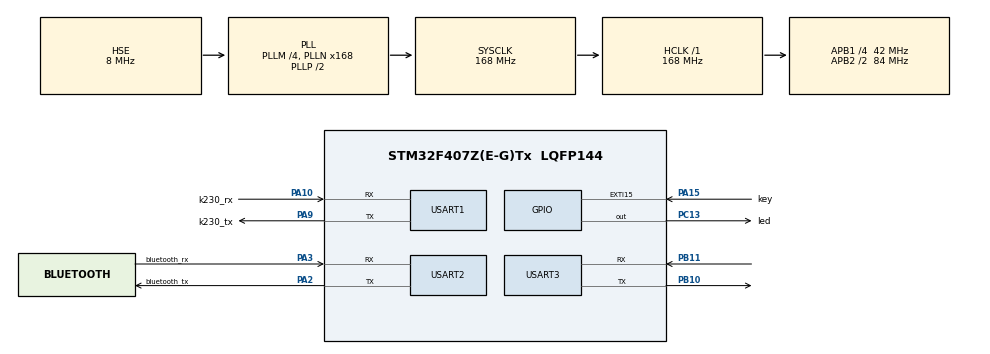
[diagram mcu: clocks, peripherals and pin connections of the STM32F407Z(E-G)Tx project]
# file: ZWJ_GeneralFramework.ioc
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Dma.Request0=USART1_RX
Dma.Request1=USART1_TX
Dma.Request2=USART2_RX
Dma.Request3=USART2_TX
Dma.USART1_RX.0.Direction=DMA_PERIPH_TO_MEMORY
Dma.USART1_RX.0.FIFOMode=DMA_FIFOMODE_DISABLE
Dma.USART1_RX.0.Instance=DMA2_Stream2
Dma.USART1_RX.0.MemDataAlignment=DMA_MDATAALIGN_BYTE
Dma.USART1_RX.0.MemInc=DMA_MINC_ENABLE
Dma.USART1_RX.0.Mode=DMA_NORMAL
Dma.USART1_RX.0.PeriphDataAlignment=DMA_PDATAALIGN_BYTE
Dma.USART1_RX.0.PeriphInc=DMA_PINC_DISABLE
Dma.USART1_RX.0.Priority=DMA_PRIORITY_LOW
Dma.USART1_TX.1.Direction=DMA_MEMORY_TO_PERIPH
Dma.USART1_TX.1.FIFOMode=DMA_FIFOMODE_DISABLE
Dma.USART1_TX.1.Instance=DMA2_Stream7
Dma.USART1_TX.1.MemDataAlignment=DMA_MDATAALIGN_BYTE
Dma.USART1_TX.1.MemInc=DMA_MINC_ENABLE
Dma.USART1_TX.1.Mode=DMA_NORMAL
Dma.USART1_TX.1.PeriphDataAlignment=DMA_PDATAALIGN_BYTE
Dma.USART1_TX.1.PeriphInc=DMA_PINC_DISABLE
Dma.USART1_TX.1.Priority=DMA_PRIORITY_LOW
Dma.USART2_RX.2.Direction=DMA_PERIPH_TO_MEMORY
Dma.USART2_RX.2.FIFOMode=DMA_FIFOMODE_DISABLE
Dma.USART2_RX.2.Instance=DMA1_Stream5
Dma.USART2_RX.2.MemDataAlignment=DMA_MDATAALIGN_BYTE
Dma.USART2_RX.2.MemInc=DMA_MINC_ENABLE
Dma.USART2_RX.2.Mode=DMA_NORMAL
Dma.USART2_RX.2.PeriphDataAlignment=DMA_PDATAALIGN_BYTE
Dma.USART2_RX.2.PeriphInc=DMA_PINC_DISABLE
Dma.USART2_RX.2.Priority=DMA_PRIORITY_LOW
Dma.USART2_TX.3.Direction=DMA_MEMORY_TO_PERIPH
Dma.USART2_TX.3.FIFOMode=DMA_FIFOMODE_DISABLE
Dma.USART2_TX.3.Instance=DMA1_Stream6
Dma.USART2_TX.3.MemDataAlignment=DMA_MDATAALIGN_BYTE
Dma.USART2_TX.3.MemInc=DMA_MINC_ENABLE
Dma.USART2_TX.3.Mode=DMA_NORMAL
Dma.USART2_TX.3.PeriphDataAlignment=DMA_PDATAALIGN_BYTE
Dma.USART2_TX.3.PeriphInc=DMA_PINC_DISABLE
Dma.USART2_TX.3.Priority=DMA_PRIORITY_LOW
FREERTOS.INCLUDE_vTaskDelayUntil=1
FREERTOS.Tasks01=ApplicationTask,0,2048,Application,Default,NULL,Dynamic,NULL,NULL;ControlTask,2,512,Control,Default,NULL,Dynamic,NULL,NULL;RobotSystemTask,-2,512,RobotSystem,Default,NULL,Dynamic,NULL,NULL;StateCoreTask,1,1024,StateCore,Default,NULL,Dynamic,NULL,NULL
FREERTOS.configTOTAL_HEAP_SIZE=20000
Mcu.Family=STM32F4
Mcu.Name=STM32F407Z(E-G)Tx
Mcu.Package=LQFP144
NVIC.DMA1_Stream5_IRQn=true\:5\:0\:false\:false\:true\:true\:false\:true\:true
NVIC.DMA1_Stream6_IRQn=true\:5\:0\:false\:false\:true\:true\:false\:true\:true
NVIC.DMA2_Stream2_IRQn=true\:5\:0\:false\:false\:true\:true\:false\:true\:true
NVIC.DMA2_Stream7_IRQn=true\:5\:0\:false\:false\:true\:true\:false\:true\:true
NVIC.EXTI15_10_IRQn=true\:5\:0\:false\:false\:true\:false\:true\:true\:true
NVIC.PriorityGroup=NVIC_PRIORITYGROUP_4
NVIC.TIM6_DAC_IRQn=true\:15\:0\:false\:false\:true\:false\:false\:true\:true
NVIC.TimeBase=TIM6_DAC_IRQn
NVIC.TimeBaseIP=TIM6
NVIC.USART1_IRQn=true\:5\:0\:false\:false\:true\:true\:true\:true\:true
NVIC.USART2_IRQn=true\:5\:0\:false\:false\:true\:true\:true\:true\:true
PA10.GPIO_Label=k230_rx
PA10.Mode=Asynchronous
PA10.Signal=USART1_RX
PA13.Mode=Serial_Wire
PA13.Signal=SYS_JTMS-SWDIO
PA14.Mode=Serial_Wire
PA14.Signal=SYS_JTCK-SWCLK
PA15.GPIO_Label=key
PA15.GPIO_ModeDefaultEXTI=GPIO_MODE_IT_FALLING
PA15.GPIO_PuPd=GPIO_PULLUP
PA15.Signal=GPXTI15
PA2.GPIO_Label=bluetooth_tx
PA2.Mode=Asynchronous
PA2.Signal=USART2_TX
PA3.GPIO_Label=bluetooth_rx
PA3.Mode=Asynchronous
PA3.Signal=USART2_RX
PA9.GPIO_Label=k230_tx
PA9.Mode=Asynchronous
PA9.Signal=USART1_TX
PB10.Mode=Asynchronous
PB10.Signal=USART3_TX
PB11.Mode=Asynchronous
PB11.Signal=USART3_RX
PC13-ANTI_TAMP.GPIO_Label=led
PC13-ANTI_TAMP.GPIO_PuPd=GPIO_PULLUP
PC13-ANTI_TAMP.PinState=GPIO_PIN_SET
PC13-ANTI_TAMP.Signal=GPIO_Output
PC14-OSC32_IN.Mode=LSE-External-Oscillator
PC14-OSC32_IN.Signal=RCC_OSC32_IN
PC15-OSC32_OUT.Mode=LSE-External-Oscillator
PC15-OSC32_OUT.Signal=RCC_OSC32_OUT
PH0-OSC_IN.Mode=HSE-External-Oscillator
PH0-OSC_IN.Signal=RCC_OSC_IN
PH1-OSC_OUT.Mode=HSE-External-Oscillator
PH1-OSC_OUT.Signal=RCC_OSC_OUT
ProjectManager.HeapSize=0x200
ProjectManager.StackSize=0x400
ProjectManager.TargetToolchain=MDK-ARM V5.32
RCC.48MHZClocksFreq_Value=84000000
RCC.AHBFreq_Value=168000000
RCC.APB1CLKDivider=RCC_HCLK_DIV4
RCC.APB1Freq_Value=42000000
RCC.APB1TimFreq_Value=84000000
RCC.APB2CLKDivider=RCC_HCLK_DIV2
RCC.APB2Freq_Value=84000000
RCC.APB2TimFreq_Value=168000000
RCC.CortexFreq_Value=168000000
RCC.HCLKFreq_Value=168000000
RCC.HSE_VALUE=8000000
RCC.HSI_VALUE=16000000
RCC.PLLM=4
RCC.PLLN=168
RCC.PLLSourceVirtual=RCC_PLLSOURCE_HSE
RCC.SYSCLKFreq_VALUE=168000000
RCC.SYSCLKSource=RCC_SYSCLKSOURCE_PLLCLK
RCC.VCOOutputFreq_Value=336000000
STMicroelectronics.X-CUBE-ALGOBUILD.1.4.0.LibraryCcDSPOoLibraryJjDSPOoLibrary=true
USART1.VirtualMode=VM_ASYNC
USART2.VirtualMode=VM_ASYNC
USART3.VirtualMode=VM_ASYNC
VP_FREERTOS_VS_CMSIS_V1.Mode=CMSIS_V1
VP_STMicroelectronics.X-CUBE-ALGOBUILD_VS_DSPOoLibraryJjLibrary_1.4.0_1.4.0.Mode=DSPOoLibraryJjLibrary
VP_SYS_VS_tim6.Mode=TIM6
board=custom

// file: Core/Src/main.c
/* USER CODE BEGIN Header */
////////////////////////////////////////////////////////////////////
//                          _ooOoo_                               //
//                         o8888888o                              //
//                         88" . "88                              //
//                         (| ^_^ |)                              //
//                         O\  =  /O                              //
//                      ____/`---'\____                           //
//                    .'  \\|     |//  `.                         //
//                   /  \\|||  :  |||//  \                        //
//                  /  _||||| -:- |||||-  \                       //
//                  |   | \\\  -  /// |   |                       //
//                  | \_|  ''\---/''  |   |                       //
//                  \  .-\__  `-`  ___/-. /                       //
//                ___`. .'  /--.--\  `. . ___                     //
//              ."" '<  `.___\_<|>_/___.'  >'"".                  //
//            | | :  `- \`.;`\ _ /`;.`/ - ` : | |                 //
//            \  \ `-.   \_ __\ /__ _/   .-` /  /                 //
//      ========`-.____`-.___\_____/___.-`____.-'========         //
//                           `=---='                              //
//      ^^^^^^^^^^^^^^^^^^^^^^^^^^^^^^^^^^^^^^^^^^^^^^^^^^        //
//          佛祖保佑          永不宕机          永无BUG            //
////////////////////////////////////////////////////////////////////
/**
 ******************************************************************************
 * @file           : main.c
 * @brief          : Main program body
 ******************************************************************************
 * @attention
 *
 * Copyright (c) 2026 STMicroelectronics.
 * All rights reserved.
 *
 * This software is licensed under terms that can be found in the LICENSE file
 * in the root directory of this software component.
 * If no LICENSE file comes with this software, it is provided AS-IS.
 *
 ******************************************************************************
 */
/* USER CODE END Header */
#include "main.h"
#include "cmsis_os.h"
#include "dma.h"
#include "usart.h"
#include "gpio.h"

/* USER CODE BEGIN Includes */
#include "std_cpp.h"
/* USER CODE END Includes */

void SystemClock_Config(void);
void MX_FREERTOS_Init(void);

int main(void)
{

  /* MCU Configuration--------------------------------------------------------*/

  /* Reset of all peripherals, Initializes the Flash interface and the Systick. */
  HAL_Init();

  /* Configure the system clock */
  SystemClock_Config();

  /* Initialize all configured peripherals */
  MX_GPIO_Init();
  MX_DMA_Init();
  MX_USART1_UART_Init();
  MX_USART2_UART_Init();
  MX_USART3_UART_Init();
  /* USER CODE BEGIN 2 */
    MainInitCpp();
  /* USER CODE END 2 */

  /* Call init function for freertos objects (in cmsis_os2.c) */
  MX_FREERTOS_Init();

  /* Start scheduler */
  osKernelStart();

  /* We should never get here as control is now taken by the scheduler */

  /* Infinite loop */
    while (1) {

    }
}

void SystemClock_Config(void)
{
  RCC_OscInitTypeDef RCC_OscInitStruct = {0};
  RCC_ClkInitTypeDef RCC_ClkInitStruct = {0};

  /** Configure the main internal regulator output voltage
  */
  __HAL_RCC_PWR_CLK_ENABLE();
  __HAL_PWR_VOLTAGESCALING_CONFIG(PWR_REGULATOR_VOLTAGE_SCALE1);

  /** Initializes the RCC Oscillators according to the specified parameters
  * in the RCC_OscInitTypeDef structure.
  */
  RCC_OscInitStruct.OscillatorType = RCC_OSCILLATORTYPE_HSE;
  RCC_OscInitStruct.HSEState = RCC_HSE_ON;
  RCC_OscInitStruct.PLL.PLLState = RCC_PLL_ON;
  RCC_OscInitStruct.PLL.PLLSource = RCC_PLLSOURCE_HSE;
  RCC_OscInitStruct.PLL.PLLM = 4;
  RCC_OscInitStruct.PLL.PLLN = 168;
  RCC_OscInitStruct.PLL.PLLP = RCC_PLLP_DIV2;
  RCC_OscInitStruct.PLL.PLLQ = 4;
  if (HAL_RCC_OscConfig(&RCC_OscInitStruct) != HAL_OK)
  {
    Error_Handler();
  }

  /** Initializes the CPU, AHB and APB buses clocks
  */
  RCC_ClkInitStruct.ClockType = RCC_CLOCKTYPE_HCLK|RCC_CLOCKTYPE_SYSCLK
                              |RCC_CLOCKTYPE_PCLK1|RCC_CLOCKTYPE_PCLK2;
  RCC_ClkInitStruct.SYSCLKSource = RCC_SYSCLKSOURCE_PLLCLK;
  RCC_ClkInitStruct.AHBCLKDivider = RCC_SYSCLK_DIV1;
  RCC_ClkInitStruct.APB1CLKDivider = RCC_HCLK_DIV4;
  RCC_ClkInitStruct.APB2CLKDivider = RCC_HCLK_DIV2;

  if (HAL_RCC_ClockConfig(&RCC_ClkInitStruct, FLASH_LATENCY_5) != HAL_OK)
  {
    Error_Handler();
  }
}

void HAL_TIM_PeriodElapsedCallback(TIM_HandleTypeDef *htim)
{
  if (htim->Instance == TIM6)
  {
    HAL_IncTick();
  }
}

void Error_Handler(void)
{
    __disable_irq();
    while (1) {
    }
}

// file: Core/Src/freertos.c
/* USER CODE BEGIN Header */
/**
 ******************************************************************************
 * File Name          : freertos.c
 * Description        : Code for freertos applications
 ******************************************************************************
 * @attention
 *
 * Copyright (c) 2026 STMicroelectronics.
 * All rights reserved.
 *
 * This software is licensed under terms that can be found in the LICENSE file
 * in the root directory of this software component.
 * If no LICENSE file comes with this software, it is provided AS-IS.
 *
 ******************************************************************************
 */
/* USER CODE END Header */

#include "FreeRTOS.h"
#include "task.h"
#include "main.h"
#include "cmsis_os.h"

/* USER CODE BEGIN Includes */
#include "std_cpp.h"
/* USER CODE END Includes */

osThreadId ApplicationTaskHandle;
osThreadId ControlTaskHandle;
osThreadId RobotSystemTaskHandle;
osThreadId StateCoreTaskHandle;

void Application(void const * argument);
void Control(void const * argument);
void RobotSystem(void const * argument);
void StateCore(void const * argument);

void MX_FREERTOS_Init(void); /* (MISRA C 2004 rule 8.1) */

/* GetIdleTaskMemory prototype (linked to static allocation support) */
void vApplicationGetIdleTaskMemory( StaticTask_t **ppxIdleTaskTCBBuffer, StackType_t **ppxIdleTaskStackBuffer, uint32_t *pulIdleTaskStackSize );

/* USER CODE BEGIN GET_IDLE_TASK_MEMORY */
static StaticTask_t xIdleTaskTCBBuffer;
static StackType_t xIdleStack[configMINIMAL_STACK_SIZE];

void vApplicationGetIdleTaskMemory(StaticTask_t **ppxIdleTaskTCBBuffer, StackType_t **ppxIdleTaskStackBuffer,
                                   uint32_t *pulIdleTaskStackSize) {
    *ppxIdleTaskTCBBuffer = &xIdleTaskTCBBuffer;
    *ppxIdleTaskStackBuffer = &xIdleStack[0];
    *pulIdleTaskStackSize = configMINIMAL_STACK_SIZE;
    /* place for user code */
}
/* USER CODE END GET_IDLE_TASK_MEMORY */

void MX_FREERTOS_Init(void) {

  /* Create the thread(s) */
  /* definition and creation of ApplicationTask */
  osThreadDef(ApplicationTask, Application, osPriorityNormal, 0, 2048);
  ApplicationTaskHandle = osThreadCreate(osThread(ApplicationTask), NULL);

  /* definition and creation of ControlTask */
  osThreadDef(ControlTask, Control, osPriorityHigh, 0, 512);
  ControlTaskHandle = osThreadCreate(osThread(ControlTask), NULL);

  /* definition and creation of RobotSystemTask */
  osThreadDef(RobotSystemTask, RobotSystem, osPriorityLow, 0, 512);
  RobotSystemTaskHandle = osThreadCreate(osThread(RobotSystemTask), NULL);

  /* definition and creation of StateCoreTask */
  osThreadDef(StateCoreTask, StateCore, osPriorityAboveNormal, 0, 1024);
  StateCoreTaskHandle = osThreadCreate(osThread(StateCoreTask), NULL);

}

void Application(void const * argument)
{
  /* USER CODE BEGIN DEFAULT_TASK_FUNCTION */
    /* Infinite loop */
    ApplicationCpp();
  /* USER CODE END DEFAULT_TASK_FUNCTION */
}

void Control(void const * argument)
{
  /* USER CODE BEGIN Control */
    /* Infinite loop */
    ControlCpp();
  /* USER CODE END Control */
}

void RobotSystem(void const * argument)
{
  /* USER CODE BEGIN RobotSystem */
    /* Infinite loop */
    RobotSystemCpp();
  /* USER CODE END RobotSystem */
}

void StateCore(void const * argument)
{
  /* USER CODE BEGIN StateCore */
    /* Infinite loop */
    StateCoreCpp();
  /* USER CODE END StateCore */
}
